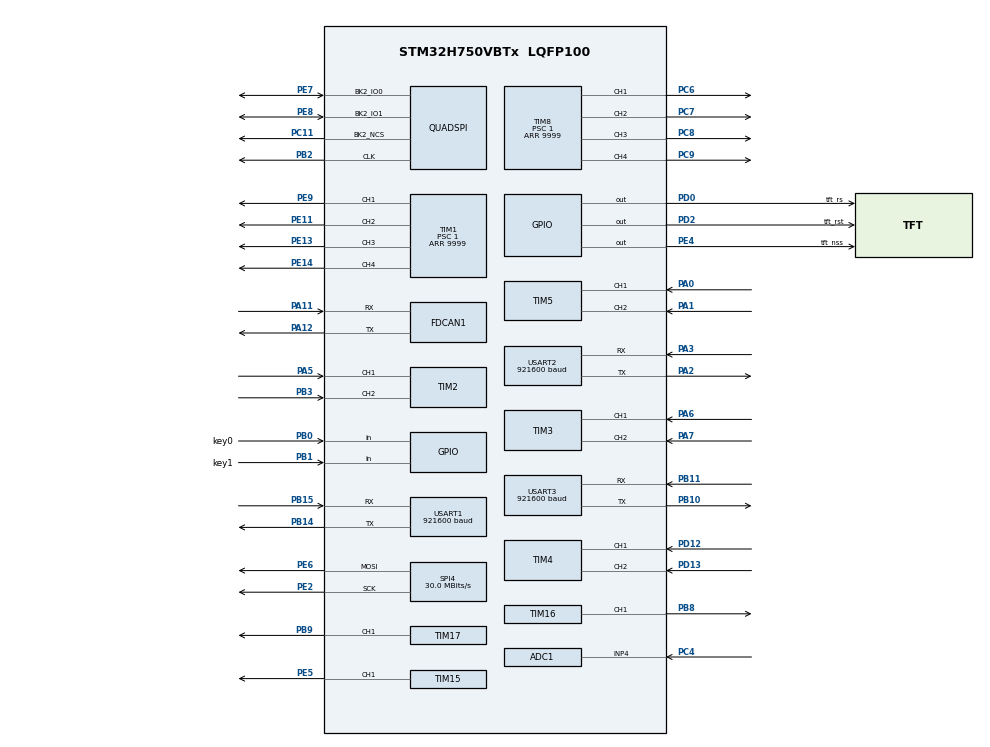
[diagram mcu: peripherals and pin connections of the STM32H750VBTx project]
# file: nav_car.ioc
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ADC1.Channel-0\#ChannelRegularConversion=ADC_CHANNEL_4
ADC1.ContinuousConvMode=ENABLE
ADC1.ConversionDataManagement=ADC_CONVERSIONDATA_DMA_CIRCULAR
ADC1.EOCSelection=ADC_EOC_SEQ_CONV
ADC1.ExternalTrigConv=ADC_SOFTWARE_START
ADC1.NbrOfConversion=1
ADC1.NbrOfConversionFlag=1
ADC1.OffsetNumber-0\#ChannelRegularConversion=ADC_OFFSET_NONE
ADC1.OffsetSignedSaturation-0\#ChannelRegularConversion=DISABLE
ADC1.Overrun=ADC_OVR_DATA_OVERWRITTEN
ADC1.Rank-0\#ChannelRegularConversion=1
ADC1.Ratio=16
ADC1.SamplingTime-0\#ChannelRegularConversion=ADC_SAMPLETIME_810CYCLES_5
ADC1.master=1
CORTEX_M7.AccessPermission_Spec=MPU_REGION_FULL_ACCESS
CORTEX_M7.BaseAddress_Spec=0x30000000
CORTEX_M7.CPU_DCache=Enabled
CORTEX_M7.CPU_ICache=Enabled
CORTEX_M7.Size_Spec=MPU_REGION_SIZE_128KB
CORTEX_M7.SubRegionDisable_Spec=0x00
CORTEX_M7.default_mode_Activation=1
Dma.ADC1.0.Direction=DMA_PERIPH_TO_MEMORY
Dma.ADC1.0.EventEnable=DISABLE
Dma.ADC1.0.FIFOMode=DMA_FIFOMODE_DISABLE
Dma.ADC1.0.Instance=DMA2_Stream0
Dma.ADC1.0.MemDataAlignment=DMA_MDATAALIGN_HALFWORD
Dma.ADC1.0.MemInc=DMA_MINC_ENABLE
Dma.ADC1.0.Mode=DMA_CIRCULAR
Dma.ADC1.0.PeriphDataAlignment=DMA_PDATAALIGN_HALFWORD
Dma.ADC1.0.PeriphInc=DMA_PINC_DISABLE
Dma.ADC1.0.Polarity=HAL_DMAMUX_REQ_GEN_RISING
Dma.ADC1.0.Priority=DMA_PRIORITY_LOW
Dma.ADC1.0.RequestNumber=1
Dma.ADC1.0.SignalID=NONE
Dma.ADC1.0.SyncEnable=DISABLE
Dma.ADC1.0.SyncPolarity=HAL_DMAMUX_SYNC_NO_EVENT
Dma.ADC1.0.SyncRequestNumber=1
Dma.ADC1.0.SyncSignalID=NONE
Dma.Request0=ADC1
Dma.Request1=TIM17_UP
Dma.TIM17_UP.1.Direction=DMA_MEMORY_TO_PERIPH
Dma.TIM17_UP.1.EventEnable=DISABLE
Dma.TIM17_UP.1.FIFOMode=DMA_FIFOMODE_DISABLE
Dma.TIM17_UP.1.Instance=DMA1_Stream0
Dma.TIM17_UP.1.MemDataAlignment=DMA_MDATAALIGN_WORD
Dma.TIM17_UP.1.MemInc=DMA_MINC_ENABLE
Dma.TIM17_UP.1.Mode=DMA_NORMAL
Dma.TIM17_UP.1.PeriphDataAlignment=DMA_PDATAALIGN_WORD
Dma.TIM17_UP.1.PeriphInc=DMA_PINC_DISABLE
Dma.TIM17_UP.1.Polarity=HAL_DMAMUX_REQ_GEN_RISING
Dma.TIM17_UP.1.Priority=DMA_PRIORITY_HIGH
Dma.TIM17_UP.1.RequestNumber=1
Dma.TIM17_UP.1.SignalID=NONE
Dma.TIM17_UP.1.SyncEnable=DISABLE
Dma.TIM17_UP.1.SyncPolarity=HAL_DMAMUX_SYNC_NO_EVENT
Dma.TIM17_UP.1.SyncRequestNumber=1
Dma.TIM17_UP.1.SyncSignalID=NONE
FDCAN1.CalculateBaudRateNominal=2604166
FDCAN1.CalculateTimeBitNominal=384
FDCAN1.CalculateTimeQuantumNominal=128.0
FREERTOS.Tasks01=lcd,8,8192,lcdTask,As weak,NULL,Dynamic,NULL,NULL;motor_control,24,1024,motorControlTask,As weak,NULL,Dynamic,NULL,NULL;uart_command,16,1024,uartCommandTask,As external,NULL,Dynamic,NULL,NULL;encoder_send,11,512,encoderSendTask,As external,NULL,Dynamic,NULL,NULL;adc,8,512,adcTask,As external,NULL,Dynamic,NULL,NULL;key,40,256,keyTask,As external,NULL,Dynamic,NULL,NULL;ws2812,9,256,ws2812Task,As external,NULL,Dynamic,NULL,NULL;beeper,10,256,beeperTask,As external,NULL,Dynamic,NULL,NULL
FREERTOS.configTOTAL_HEAP_SIZE=61440
Mcu.Family=STM32H7
Mcu.Name=STM32H750VBTx
Mcu.Package=LQFP100
NVIC.DMA2_Stream0_IRQn=true\:5\:0\:false\:false\:true\:false\:true\:true\:true
NVIC.PriorityGroup=NVIC_PRIORITYGROUP_4
NVIC.TIM6_DAC_IRQn=true\:5\:0\:false\:false\:true\:true\:true\:true\:true
NVIC.TIM7_IRQn=true\:15\:0\:false\:false\:true\:false\:false\:true\:true
NVIC.TimeBase=TIM7_IRQn
NVIC.TimeBaseIP=TIM7
NVIC.USART1_IRQn=true\:5\:0\:false\:false\:true\:true\:true\:true\:true
NVIC.USART2_IRQn=true\:5\:0\:false\:false\:true\:true\:true\:true\:true
PA0.PinAttribute=Free
PA0.Signal=S_TIM5_CH1
PA1.PinAttribute=Free
PA1.Signal=S_TIM5_CH2
PA11.Mode=FDCAN_Activate
PA11.Signal=FDCAN1_RX
PA12.Mode=FDCAN_Activate
PA12.Signal=FDCAN1_TX
PA13\ (JTMS/SWDIO).Mode=Serial_Wire
PA13\ (JTMS/SWDIO).Signal=DEBUG_JTMS-SWDIO
PA14\ (JTCK/SWCLK).Mode=Serial_Wire
PA14\ (JTCK/SWCLK).Signal=DEBUG_JTCK-SWCLK
PA2.Mode=Asynchronous
PA2.Signal=USART2_TX
PA3.Mode=Asynchronous
PA3.Signal=USART2_RX
PA5.Signal=S_TIM2_CH1_ETR
PA6.Signal=S_TIM3_CH1
PA7.Signal=S_TIM3_CH2
PB0.GPIO_Label=key0
PB0.Signal=GPIO_Input
PB1.GPIO_Label=key1
PB1.Signal=GPIO_Input
PB10.Mode=Asynchronous
PB10.Signal=USART3_TX
PB11.Mode=Asynchronous
PB11.Signal=USART3_RX
PB14.Mode=Asynchronous
PB14.Signal=USART1_TX
PB15.Mode=Asynchronous
PB15.Signal=USART1_RX
PB2.GPIO_Speed=GPIO_SPEED_FREQ_VERY_HIGH
PB2.Mode=Single Bank 2 2IOs
PB2.Signal=QUADSPI_CLK
PB3\ (JTDO/TRACESWO).Signal=S_TIM2_CH2
PB8.Signal=S_TIM16_CH1
PB9.Signal=S_TIM17_CH1
PC11.GPIO_PuPd=GPIO_PULLUP
PC11.GPIO_Speed=GPIO_SPEED_FREQ_VERY_HIGH
PC11.Mode=Single Bank 2 2IOs
PC11.Signal=QUADSPI_BK2_NCS
PC4.Signal=ADCx_INP4
PC6.Signal=S_TIM8_CH1
PC7.Signal=S_TIM8_CH2
PC8.Signal=S_TIM8_CH3
PC9.Signal=S_TIM8_CH4
PD0.GPIO_Label=tft_rs
PD0.GPIO_Speed=GPIO_SPEED_FREQ_VERY_HIGH
PD0.PinState=GPIO_PIN_SET
PD0.Signal=GPIO_Output
PD12.Signal=S_TIM4_CH1
PD13.Signal=S_TIM4_CH2
PD2.GPIO_Label=tft_rst
PD2.GPIO_Speed=GPIO_SPEED_FREQ_VERY_HIGH
PD2.PinState=GPIO_PIN_SET
PD2.Signal=GPIO_Output
PE11.Signal=S_TIM1_CH2
PE13.Signal=S_TIM1_CH3
PE14.Signal=S_TIM1_CH4
PE2.Mode=TX_Only_Simplex_Unidirect_Master
PE2.PinAttribute=Free
PE2.Signal=SPI4_SCK
PE4.GPIO_Label=tft_nss
PE4.GPIO_Speed=GPIO_SPEED_FREQ_VERY_HIGH
PE4.PinAttribute=Free
PE4.PinState=GPIO_PIN_SET
PE4.Signal=GPIO_Output
PE5.PinAttribute=Free
PE5.Signal=S_TIM15_CH1
PE6.Mode=TX_Only_Simplex_Unidirect_Master
PE6.PinAttribute=Free
PE6.Signal=SPI4_MOSI
PE7.GPIO_Speed=GPIO_SPEED_FREQ_VERY_HIGH
PE7.Mode=Single Bank 2 2IOs
PE7.Signal=QUADSPI_BK2_IO0
PE8.GPIO_Speed=GPIO_SPEED_FREQ_VERY_HIGH
PE8.Mode=Single Bank 2 2IOs
PE8.Signal=QUADSPI_BK2_IO1
PE9.Signal=S_TIM1_CH1
PH0-OSC_IN\ (PH0).Mode=HSE-External-Oscillator
PH0-OSC_IN\ (PH0).PinAttribute=Free
PH0-OSC_IN\ (PH0).Signal=RCC_OSC_IN
PH1-OSC_OUT\ (PH1).Mode=HSE-External-Oscillator
PH1-OSC_OUT\ (PH1).PinAttribute=Free
PH1-OSC_OUT\ (PH1).Signal=RCC_OSC_OUT
ProjectManager.HeapSize=0x1000
ProjectManager.StackSize=0x400
ProjectManager.TargetToolchain=CMake
QUADSPI.ClockPrescaler=1
QUADSPI.FifoThreshold=4
QUADSPI.FlashSize=24
QUADSPI.SampleShifting=QSPI_SAMPLE_SHIFTING_HALFCYCLE
RCC.ADCFreq_Value=25000000
RCC.APB1Freq_Value=120000000
RCC.APB2Freq_Value=120000000
RCC.APB3Freq_Value=120000000
RCC.APB4Freq_Value=120000000
RCC.CortexFreq_Value=480000000
RCC.D1PPRE=RCC_APB3_DIV2
RCC.D2PPRE1=RCC_APB1_DIV2
RCC.D2PPRE2=RCC_APB2_DIV2
RCC.D3PPRE=RCC_APB4_DIV2
RCC.DIVM1=5
RCC.DIVM2=2
RCC.DIVM3=5
RCC.DIVN1=192
RCC.DIVN2=40
RCC.DIVN3=70
RCC.DIVP2=20
RCC.DIVQ1=5
RCC.DIVQ2=4
RCC.DIVQ3=5
RCC.DIVR2=5
RCC.DIVR3=5
RCC.EnbaleCSS=true
RCC.FDCANCLockSelection=RCC_FDCANCLKSOURCE_PLL2
RCC.HCLKFreq_Value=240000000
RCC.HPRE=RCC_HCLK_DIV2
RCC.PLL2FRACN=0
RCC.PLL3FRACN=0
RCC.PLLFRACN=0
RCC.PLLSourceVirtual=RCC_PLLSOURCE_HSE
RCC.QSPICLockSelection=RCC_QSPICLKSOURCE_PLL2
RCC.SYSCLKFreq_VALUE=480000000
RCC.SYSCLKSource=RCC_SYSCLKSOURCE_PLLCLK
RCC.USART234578CLockSelection=RCC_USART234578CLKSOURCE_PLL3
RCC.USBFreq_Value=192000000
SH.ADCx_INP4.0=ADC1_INP4,IN4-Single-Ended
SH.S_TIM15_CH1.0=TIM15_CH1,PWM Generation1 CH1
SH.S_TIM16_CH1.0=TIM16_CH1,PWM Generation1 CH1
SH.S_TIM17_CH1.0=TIM17_CH1,PWM Generation1 CH1
SH.S_TIM1_CH1.0=TIM1_CH1,PWM Generation1 CH1
SH.S_TIM1_CH2.0=TIM1_CH2,PWM Generation2 CH2
SH.S_TIM1_CH3.0=TIM1_CH3,PWM Generation3 CH3
SH.S_TIM1_CH4.0=TIM1_CH4,PWM Generation4 CH4
SH.S_TIM2_CH1_ETR.0=TIM2_CH1,Encoder_Interface
SH.S_TIM2_CH2.0=TIM2_CH2,Encoder_Interface
SH.S_TIM3_CH1.0=TIM3_CH1,Encoder_Interface
SH.S_TIM3_CH2.0=TIM3_CH2,Encoder_Interface
SH.S_TIM4_CH1.0=TIM4_CH1,Encoder_Interface
SH.S_TIM4_CH2.0=TIM4_CH2,Encoder_Interface
SH.S_TIM5_CH1.0=TIM5_CH1,Encoder_Interface
SH.S_TIM5_CH2.0=TIM5_CH2,Encoder_Interface
SH.S_TIM8_CH1.0=TIM8_CH1,PWM Generation1 CH1
SH.S_TIM8_CH2.0=TIM8_CH2,PWM Generation2 CH2
SH.S_TIM8_CH3.0=TIM8_CH3,PWM Generation3 CH3
SH.S_TIM8_CH4.0=TIM8_CH4,PWM Generation4 CH4
SPI4.BaudRatePrescaler=SPI_BAUDRATEPRESCALER_4
SPI4.CalculateBaudRate=30.0 MBits/s
SPI4.DataSize=SPI_DATASIZE_8BIT
SPI4.Direction=SPI_DIRECTION_2LINES_TXONLY
SPI4.Mode=SPI_MODE_MASTER
SPI4.VirtualType=VM_MASTER
TIM1.AutoReloadPreload=TIM_AUTORELOAD_PRELOAD_ENABLE
TIM1.Channel-PWM\ Generation1\ CH1=TIM_CHANNEL_1
TIM1.Channel-PWM\ Generation2\ CH2=TIM_CHANNEL_2
TIM1.Channel-PWM\ Generation3\ CH3=TIM_CHANNEL_3
TIM1.Channel-PWM\ Generation4\ CH4=TIM_CHANNEL_4
TIM1.Period=9999
TIM1.Prescaler=1
TIM12.AutoReloadPreload=TIM_AUTORELOAD_PRELOAD_ENABLE
TIM12.Period=65535
TIM12.Prescaler=239
TIM12.TIM_MasterOutputTrigger=TIM_TRGO_UPDATE
TIM12.TIM_MasterSlaveMode=TIM_MASTERSLAVEMODE_ENABLE
TIM15.Channel-PWM\ Generation1\ CH1=TIM_CHANNEL_1
TIM15.Period=49
TIM15.Prescaler=119
TIM16.Channel=TIM_CHANNEL_1
TIM16.Prescaler=239
TIM17.Channel=TIM_CHANNEL_1
TIM17.Period=299
TIM6.AutoReloadPreload=TIM_AUTORELOAD_PRELOAD_ENABLE
TIM6.Period=999
TIM6.Prescaler=239
TIM6.TIM_MasterOutputTrigger=TIM_TRGO_UPDATE
TIM8.AutoReloadPreload=TIM_AUTORELOAD_PRELOAD_ENABLE
TIM8.Channel-PWM\ Generation1\ CH1=TIM_CHANNEL_1
TIM8.Channel-PWM\ Generation2\ CH2=TIM_CHANNEL_2
TIM8.Channel-PWM\ Generation3\ CH3=TIM_CHANNEL_3
TIM8.Channel-PWM\ Generation4\ CH4=TIM_CHANNEL_4
TIM8.Period=9999
TIM8.Prescaler=1
USART1.BaudRate=921600
USART1.VirtualMode-Asynchronous=VM_ASYNC
USART2.BaudRate=921600
USART2.VirtualMode-Asynchronous=VM_ASYNC
USART3.BaudRate=921600
USART3.VirtualMode-Asynchronous=VM_ASYNC
VP_CRC_VS_CRC.Mode=CRC_Activate
VP_FREERTOS_VS_CMSIS_V2.Mode=CMSIS_V2
VP_MEMORYMAP_VS_MEMORYMAP.Mode=CurAppReg
VP_SYS_VS_tim7.Mode=TIM7
VP_TIM12_VS_ClockSourceINT.Mode=Internal
VP_TIM15_VS_ClockSourceINT.Mode=Internal
VP_TIM16_VS_ClockSourceINT.Mode=Enable_Timer
VP_TIM17_VS_ClockSourceINT.Mode=Enable_Timer
VP_TIM6_VS_ClockSourceINT.Mode=Enable_Timer
board=custom

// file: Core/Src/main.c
/* USER CODE BEGIN Header */
/**
  ******************************************************************************
  * @file           : main.c
  * @brief          : Main program body
  ******************************************************************************
  * @attention
  *
  * Copyright (c) 2026 STMicroelectronics.
  * All rights reserved.
  *
  * This software is licensed under terms that can be found in the LICENSE file
  * in the root directory of this software component.
  * If no LICENSE file comes with this software, it is provided AS-IS.
  *
  ******************************************************************************
  */
/* USER CODE END Header */
#include "main.h"
#include "FreeRTOS.h"
#include "cmsis_os2.h"

/* USER CODE BEGIN Includes */
#include <stdio.h>
/* USER CODE END Includes */

ADC_HandleTypeDef hadc1;
DMA_HandleTypeDef hdma_adc1;

CRC_HandleTypeDef hcrc;

FDCAN_HandleTypeDef hfdcan1;

QSPI_HandleTypeDef hqspi;

SPI_HandleTypeDef hspi4;

TIM_HandleTypeDef htim1;
TIM_HandleTypeDef htim2;
TIM_HandleTypeDef htim3;
TIM_HandleTypeDef htim4;
TIM_HandleTypeDef htim5;
TIM_HandleTypeDef htim6;
TIM_HandleTypeDef htim8;
TIM_HandleTypeDef htim12;
TIM_HandleTypeDef htim15;
TIM_HandleTypeDef htim16;
TIM_HandleTypeDef htim17;
DMA_HandleTypeDef hdma_tim17_up;

UART_HandleTypeDef huart1;
UART_HandleTypeDef huart2;
UART_HandleTypeDef huart3;

/* Definitions for lcd */
osThreadId_t lcdHandle;
const osThreadAttr_t lcd_attributes = {
  .name = "lcd",
  .stack_size = 8192 * 4,
  .priority = (osPriority_t) osPriorityLow,
};
/* Definitions for motor_control */
osThreadId_t motor_controlHandle;
const osThreadAttr_t motor_control_attributes = {
  .name = "motor_control",
  .stack_size = 1024 * 4,
  .priority = (osPriority_t) osPriorityNormal,
};
/* Definitions for uart_command */
osThreadId_t uart_commandHandle;
const osThreadAttr_t uart_command_attributes = {
  .name = "uart_command",
  .stack_size = 1024 * 4,
  .priority = (osPriority_t) osPriorityBelowNormal,
};
/* Definitions for encoder_send */
osThreadId_t encoder_sendHandle;
const osThreadAttr_t encoder_send_attributes = {
  .name = "encoder_send",
  .stack_size = 512 * 4,
  .priority = (osPriority_t) osPriorityLow3,
};
/* Definitions for adc */
osThreadId_t adcHandle;
const osThreadAttr_t adc_attributes = {
  .name = "adc",
  .stack_size = 512 * 4,
  .priority = (osPriority_t) osPriorityLow,
};
/* Definitions for key */
osThreadId_t keyHandle;
const osThreadAttr_t key_attributes = {
  .name = "key",
  .stack_size = 256 * 4,
  .priority = (osPriority_t) osPriorityHigh,
};
/* Definitions for ws2812 */
osThreadId_t ws2812Handle;
const osThreadAttr_t ws2812_attributes = {
  .name = "ws2812",
  .stack_size = 256 * 4,
  .priority = (osPriority_t) osPriorityLow1,
};
/* Definitions for beeper */
osThreadId_t beeperHandle;
const osThreadAttr_t beeper_attributes = {
  .name = "beeper",
  .stack_size = 256 * 4,
  .priority = (osPriority_t) osPriorityLow2,
};

void SystemClock_Config(void);
void PeriphCommonClock_Config(void);
static void MPU_Config(void);
static void MX_GPIO_Init(void);
static void MX_DMA_Init(void);
static void MX_TIM1_Init(void);
static void MX_TIM2_Init(void);
static void MX_TIM3_Init(void);
static void MX_TIM4_Init(void);
static void MX_TIM5_Init(void);
static void MX_TIM6_Init(void);
static void MX_USART1_UART_Init(void);
static void MX_USART2_UART_Init(void);
static void MX_USART3_UART_Init(void);
static void MX_CRC_Init(void);
static void MX_FDCAN1_Init(void);
static void MX_TIM8_Init(void);
static void MX_ADC1_Init(void);
static void MX_QUADSPI_Init(void);
static void MX_SPI4_Init(void);
static void MX_TIM15_Init(void);
static void MX_TIM16_Init(void);
static void MX_TIM12_Init(void);
static void MX_TIM17_Init(void);
void lcdTask(void *argument);
void motorControlTask(void *argument);
extern void uartCommandTask(void *argument);
extern void encoderSendTask(void *argument);
extern void adcTask(void *argument);
extern void keyTask(void *argument);
extern void ws2812Task(void *argument);
extern void beeperTask(void *argument);

/* USER CODE BEGIN 0 */
volatile uint64_t timestamp_us = 0; // 全局 64-bit 时间戳（微秒）
volatile uint32_t runtime_base32 = 0; // FreeRTOS 统计用 32-bit 时间戳（微秒）
/* USER CODE END 0 */

int main(void)
{

  /* MPU Configuration--------------------------------------------------------*/
  MPU_Config();

  /* Enable the CPU Cache */

  /* Enable I-Cache---------------------------------------------------------*/
  SCB_EnableICache();

  /* Enable D-Cache---------------------------------------------------------*/
  SCB_EnableDCache();

  /* MCU Configuration--------------------------------------------------------*/

  /* Reset of all peripherals, Initializes the Flash interface and the Systick. */
  HAL_Init();

  /* Configure the system clock */
  SystemClock_Config();

  /* Configure the peripherals common clocks */
  PeriphCommonClock_Config();

  /* Initialize all configured peripherals */
  MX_GPIO_Init();
  MX_DMA_Init();
  MX_TIM1_Init();
  MX_TIM2_Init();
  MX_TIM3_Init();
  MX_TIM4_Init();
  MX_TIM5_Init();
  MX_TIM6_Init();
  MX_USART1_UART_Init();
  MX_USART2_UART_Init();
  MX_USART3_UART_Init();
  MX_CRC_Init();
  MX_FDCAN1_Init();
  MX_TIM8_Init();
  MX_ADC1_Init();
  MX_QUADSPI_Init();
  MX_SPI4_Init();
  MX_TIM15_Init();
  MX_TIM16_Init();
  MX_TIM12_Init();
  MX_TIM17_Init();
  /* USER CODE BEGIN 2 */
    __HAL_TIM_SET_COUNTER(&htim12, 0);
    __HAL_TIM_CLEAR_FLAG(&htim12, TIM_FLAG_UPDATE);
    HAL_TIM_Base_Start_IT(&htim12);
  /* USER CODE END 2 */

  /* Init scheduler */
  osKernelInitialize();

  /* Create the thread(s) */
  /* creation of lcd */
  lcdHandle = osThreadNew(lcdTask, NULL, &lcd_attributes);

  /* creation of motor_control */
  motor_controlHandle = osThreadNew(motorControlTask, NULL, &motor_control_attributes);

  /* creation of uart_command */
  uart_commandHandle = osThreadNew(uartCommandTask, NULL, &uart_command_attributes);

  /* creation of encoder_send */
  encoder_sendHandle = osThreadNew(encoderSendTask, NULL, &encoder_send_attributes);

  /* creation of adc */
  adcHandle = osThreadNew(adcTask, NULL, &adc_attributes);

  /* creation of key */
  keyHandle = osThreadNew(keyTask, NULL, &key_attributes);

  /* creation of ws2812 */
  ws2812Handle = osThreadNew(ws2812Task, NULL, &ws2812_attributes);

  /* creation of beeper */
  beeperHandle = osThreadNew(beeperTask, NULL, &beeper_attributes);

  /* Start scheduler */
  osKernelStart();

  /* We should never get here as control is now taken by the scheduler */

  /* Infinite loop */
  while (1)
  {

  }
}

void SystemClock_Config(void)
{
  RCC_OscInitTypeDef RCC_OscInitStruct = {0};
  RCC_ClkInitTypeDef RCC_ClkInitStruct = {0};

  /** Supply configuration update enable
  */
  HAL_PWREx_ConfigSupply(PWR_LDO_SUPPLY);

  /** Configure the main internal regulator output voltage
  */
  __HAL_PWR_VOLTAGESCALING_CONFIG(PWR_REGULATOR_VOLTAGE_SCALE0);

  while(!__HAL_PWR_GET_FLAG(PWR_FLAG_VOSRDY)) {}

  /** Initializes the RCC Oscillators according to the specified parameters
  * in the RCC_OscInitTypeDef structure.
  */
  RCC_OscInitStruct.OscillatorType = RCC_OSCILLATORTYPE_HSE;
  RCC_OscInitStruct.HSEState = RCC_HSE_ON;
  RCC_OscInitStruct.PLL.PLLState = RCC_PLL_ON;
  RCC_OscInitStruct.PLL.PLLSource = RCC_PLLSOURCE_HSE;
  RCC_OscInitStruct.PLL.PLLM = 5;
  RCC_OscInitStruct.PLL.PLLN = 192;
  RCC_OscInitStruct.PLL.PLLP = 2;
  RCC_OscInitStruct.PLL.PLLQ = 5;
  RCC_OscInitStruct.PLL.PLLR = 2;
  RCC_OscInitStruct.PLL.PLLRGE = RCC_PLL1VCIRANGE_2;
  RCC_OscInitStruct.PLL.PLLVCOSEL = RCC_PLL1VCOWIDE;
  RCC_OscInitStruct.PLL.PLLFRACN = 0;
  if (HAL_RCC_OscConfig(&RCC_OscInitStruct) != HAL_OK)
  {
    Error_Handler();
  }

  /** Initializes the CPU, AHB and APB buses clocks
  */
  RCC_ClkInitStruct.ClockType = RCC_CLOCKTYPE_HCLK|RCC_CLOCKTYPE_SYSCLK
                              |RCC_CLOCKTYPE_PCLK1|RCC_CLOCKTYPE_PCLK2
                              |RCC_CLOCKTYPE_D3PCLK1|RCC_CLOCKTYPE_D1PCLK1;
  RCC_ClkInitStruct.SYSCLKSource = RCC_SYSCLKSOURCE_PLLCLK;
  RCC_ClkInitStruct.SYSCLKDivider = RCC_SYSCLK_DIV1;
  RCC_ClkInitStruct.AHBCLKDivider = RCC_HCLK_DIV2;
  RCC_ClkInitStruct.APB3CLKDivider = RCC_APB3_DIV2;
  RCC_ClkInitStruct.APB1CLKDivider = RCC_APB1_DIV2;
  RCC_ClkInitStruct.APB2CLKDivider = RCC_APB2_DIV2;
  RCC_ClkInitStruct.APB4CLKDivider = RCC_APB4_DIV2;

  if (HAL_RCC_ClockConfig(&RCC_ClkInitStruct, FLASH_LATENCY_4) != HAL_OK)
  {
    Error_Handler();
  }

  /** Enables the Clock Security System
  */
  HAL_RCC_EnableCSS();
}

void PeriphCommonClock_Config(void)
{
  RCC_PeriphCLKInitTypeDef PeriphClkInitStruct = {0};

  /** Initializes the peripherals clock
  */
  PeriphClkInitStruct.PeriphClockSelection = RCC_PERIPHCLK_QSPI|RCC_PERIPHCLK_ADC
                              |RCC_PERIPHCLK_FDCAN|RCC_PERIPHCLK_USART2
                              |RCC_PERIPHCLK_USART3;
  PeriphClkInitStruct.PLL2.PLL2M = 2;
  PeriphClkInitStruct.PLL2.PLL2N = 40;
  PeriphClkInitStruct.PLL2.PLL2P = 20;
  PeriphClkInitStruct.PLL2.PLL2Q = 4;
  PeriphClkInitStruct.PLL2.PLL2R = 5;
  PeriphClkInitStruct.PLL2.PLL2RGE = RCC_PLL2VCIRANGE_3;
  PeriphClkInitStruct.PLL2.PLL2VCOSEL = RCC_PLL2VCOWIDE;
  PeriphClkInitStruct.PLL2.PLL2FRACN = 0;
  PeriphClkInitStruct.PLL3.PLL3M = 5;
  PeriphClkInitStruct.PLL3.PLL3N = 70;
  PeriphClkInitStruct.PLL3.PLL3P = 2;
  PeriphClkInitStruct.PLL3.PLL3Q = 5;
  PeriphClkInitStruct.PLL3.PLL3R = 5;
  PeriphClkInitStruct.PLL3.PLL3RGE = RCC_PLL3VCIRANGE_2;
  PeriphClkInitStruct.PLL3.PLL3VCOSEL = RCC_PLL3VCOWIDE;
  PeriphClkInitStruct.PLL3.PLL3FRACN = 0;
  PeriphClkInitStruct.QspiClockSelection = RCC_QSPICLKSOURCE_PLL2;
  PeriphClkInitStruct.FdcanClockSelection = RCC_FDCANCLKSOURCE_PLL2;
  PeriphClkInitStruct.Usart234578ClockSelection = RCC_USART234578CLKSOURCE_PLL3;
  PeriphClkInitStruct.AdcClockSelection = RCC_ADCCLKSOURCE_PLL2;
  if (HAL_RCCEx_PeriphCLKConfig(&PeriphClkInitStruct) != HAL_OK)
  {
    Error_Handler();
  }
}

static void MX_ADC1_Init(void)
{

  ADC_MultiModeTypeDef multimode = {0};
  ADC_ChannelConfTypeDef sConfig = {0};

  /** Common config
  */
  hadc1.Instance = ADC1;
  hadc1.Init.ClockPrescaler = ADC_CLOCK_ASYNC_DIV1;
  hadc1.Init.Resolution = ADC_RESOLUTION_16B;
  hadc1.Init.ScanConvMode = ADC_SCAN_DISABLE;
  hadc1.Init.EOCSelection = ADC_EOC_SEQ_CONV;
  hadc1.Init.LowPowerAutoWait = DISABLE;
  hadc1.Init.ContinuousConvMode = ENABLE;
  hadc1.Init.NbrOfConversion = 1;
  hadc1.Init.DiscontinuousConvMode = DISABLE;
  hadc1.Init.ExternalTrigConv = ADC_SOFTWARE_START;
  hadc1.Init.ExternalTrigConvEdge = ADC_EXTERNALTRIGCONVEDGE_NONE;
  hadc1.Init.ConversionDataManagement = ADC_CONVERSIONDATA_DMA_CIRCULAR;
  hadc1.Init.Overrun = ADC_OVR_DATA_OVERWRITTEN;
  hadc1.Init.LeftBitShift = ADC_LEFTBITSHIFT_NONE;
  hadc1.Init.OversamplingMode = DISABLE;
  hadc1.Init.Oversampling.Ratio = 16;
  if (HAL_ADC_Init(&hadc1) != HAL_OK)
  {
    Error_Handler();
  }

  /** Configure the ADC multi-mode
  */
  multimode.Mode = ADC_MODE_INDEPENDENT;
  if (HAL_ADCEx_MultiModeConfigChannel(&hadc1, &multimode) != HAL_OK)
  {
    Error_Handler();
  }

  /** Configure Regular Channel
  */
  sConfig.Channel = ADC_CHANNEL_4;
  sConfig.Rank = ADC_REGULAR_RANK_1;
  sConfig.SamplingTime = ADC_SAMPLETIME_810CYCLES_5;
  sConfig.SingleDiff = ADC_SINGLE_ENDED;
  sConfig.OffsetNumber = ADC_OFFSET_NONE;
  sConfig.Offset = 0;
  sConfig.OffsetSignedSaturation = DISABLE;
  if (HAL_ADC_ConfigChannel(&hadc1, &sConfig) != HAL_OK)
  {
    Error_Handler();
  }

}

static void MX_CRC_Init(void)
{

  hcrc.Instance = CRC;
  hcrc.Init.DefaultPolynomialUse = DEFAULT_POLYNOMIAL_ENABLE;
  hcrc.Init.DefaultInitValueUse = DEFAULT_INIT_VALUE_ENABLE;
  hcrc.Init.InputDataInversionMode = CRC_INPUTDATA_INVERSION_NONE;
  hcrc.Init.OutputDataInversionMode = CRC_OUTPUTDATA_INVERSION_DISABLE;
  hcrc.InputDataFormat = CRC_INPUTDATA_FORMAT_BYTES;
  if (HAL_CRC_Init(&hcrc) != HAL_OK)
  {
    Error_Handler();
  }

}

static void MX_FDCAN1_Init(void)
{

  hfdcan1.Instance = FDCAN1;
  hfdcan1.Init.FrameFormat = FDCAN_FRAME_CLASSIC;
  hfdcan1.Init.Mode = FDCAN_MODE_NORMAL;
  hfdcan1.Init.AutoRetransmission = DISABLE;
  hfdcan1.Init.TransmitPause = DISABLE;
  hfdcan1.Init.ProtocolException = DISABLE;
  hfdcan1.Init.NominalPrescaler = 16;
  hfdcan1.Init.NominalSyncJumpWidth = 1;
  hfdcan1.Init.NominalTimeSeg1 = 1;
  hfdcan1.Init.NominalTimeSeg2 = 1;
  hfdcan1.Init.DataPrescaler = 1;
  hfdcan1.Init.DataSyncJumpWidth = 1;
  hfdcan1.Init.DataTimeSeg1 = 1;
  hfdcan1.Init.DataTimeSeg2 = 1;
  hfdcan1.Init.MessageRAMOffset = 0;
  hfdcan1.Init.StdFiltersNbr = 0;
  hfdcan1.Init.ExtFiltersNbr = 0;
  hfdcan1.Init.RxFifo0ElmtsNbr = 0;
  hfdcan1.Init.RxFifo0ElmtSize = FDCAN_DATA_BYTES_8;
  hfdcan1.Init.RxFifo1ElmtsNbr = 0;
  hfdcan1.Init.RxFifo1ElmtSize = FDCAN_DATA_BYTES_8;
  hfdcan1.Init.RxBuffersNbr = 0;
  hfdcan1.Init.RxBufferSize = FDCAN_DATA_BYTES_8;
  hfdcan1.Init.TxEventsNbr = 0;
  hfdcan1.Init.TxBuffersNbr = 0;
  hfdcan1.Init.TxFifoQueueElmtsNbr = 0;
  hfdcan1.Init.TxFifoQueueMode = FDCAN_TX_FIFO_OPERATION;
  hfdcan1.Init.TxElmtSize = FDCAN_DATA_BYTES_8;
  if (HAL_FDCAN_Init(&hfdcan1) != HAL_OK)
  {
    Error_Handler();
  }

}

static void MX_QUADSPI_Init(void)
{

  /* QUADSPI parameter configuration*/
  hqspi.Instance = QUADSPI;
  hqspi.Init.ClockPrescaler = 1;
  hqspi.Init.FifoThreshold = 4;
  hqspi.Init.SampleShifting = QSPI_SAMPLE_SHIFTING_HALFCYCLE;
  hqspi.Init.FlashSize = 24;
  hqspi.Init.ChipSelectHighTime = QSPI_CS_HIGH_TIME_1_CYCLE;
  hqspi.Init.ClockMode = QSPI_CLOCK_MODE_0;
  hqspi.Init.FlashID = QSPI_FLASH_ID_2;
  hqspi.Init.DualFlash = QSPI_DUALFLASH_DISABLE;
  if (HAL_QSPI_Init(&hqspi) != HAL_OK)
  {
    Error_Handler();
  }

}

static void MX_SPI4_Init(void)
{

  /* SPI4 parameter configuration*/
  hspi4.Instance = SPI4;
  hspi4.Init.Mode = SPI_MODE_MASTER;
  hspi4.Init.Direction = SPI_DIRECTION_2LINES_TXONLY;
  hspi4.Init.DataSize = SPI_DATASIZE_8BIT;
  hspi4.Init.CLKPolarity = SPI_POLARITY_LOW;
  hspi4.Init.CLKPhase = SPI_PHASE_1EDGE;
  hspi4.Init.NSS = SPI_NSS_SOFT;
  hspi4.Init.BaudRatePrescaler = SPI_BAUDRATEPRESCALER_4;
  hspi4.Init.FirstBit = SPI_FIRSTBIT_MSB;
  hspi4.Init.TIMode = SPI_TIMODE_DISABLE;
  hspi4.Init.CRCCalculation = SPI_CRCCALCULATION_DISABLE;
  hspi4.Init.CRCPolynomial = 0x0;
  hspi4.Init.NSSPMode = SPI_NSS_PULSE_ENABLE;
  hspi4.Init.NSSPolarity = SPI_NSS_POLARITY_LOW;
  hspi4.Init.FifoThreshold = SPI_FIFO_THRESHOLD_01DATA;
  hspi4.Init.TxCRCInitializationPattern = SPI_CRC_INITIALIZATION_ALL_ZERO_PATTERN;
  hspi4.Init.RxCRCInitializationPattern = SPI_CRC_INITIALIZATION_ALL_ZERO_PATTERN;
  hspi4.Init.MasterSSIdleness = SPI_MASTER_SS_IDLENESS_00CYCLE;
  hspi4.Init.MasterInterDataIdleness = SPI_MASTER_INTERDATA_IDLENESS_00CYCLE;
  hspi4.Init.MasterReceiverAutoSusp = SPI_MASTER_RX_AUTOSUSP_DISABLE;
  hspi4.Init.MasterKeepIOState = SPI_MASTER_KEEP_IO_STATE_DISABLE;
  hspi4.Init.IOSwap = SPI_IO_SWAP_DISABLE;
  if (HAL_SPI_Init(&hspi4) != HAL_OK)
  {
    Error_Handler();
  }

}

static void MX_TIM1_Init(void)
{

  TIM_MasterConfigTypeDef sMasterConfig = {0};
  TIM_OC_InitTypeDef sConfigOC = {0};
  TIM_BreakDeadTimeConfigTypeDef sBreakDeadTimeConfig = {0};

  htim1.Instance = TIM1;
  htim1.Init.Prescaler = 1;
  htim1.Init.CounterMode = TIM_COUNTERMODE_UP;
  htim1.Init.Period = 9999;
  htim1.Init.ClockDivision = TIM_CLOCKDIVISION_DIV1;
  htim1.Init.RepetitionCounter = 0;
  htim1.Init.AutoReloadPreload = TIM_AUTORELOAD_PRELOAD_ENABLE;
  if (HAL_TIM_PWM_Init(&htim1) != HAL_OK)
  {
    Error_Handler();
  }
  sMasterConfig.MasterOutputTrigger = TIM_TRGO_RESET;
  sMasterConfig.MasterOutputTrigger2 = TIM_TRGO2_RESET;
  sMasterConfig.MasterSlaveMode = TIM_MASTERSLAVEMODE_DISABLE;
  if (HAL_TIMEx_MasterConfigSynchronization(&htim1, &sMasterConfig) != HAL_OK)
  {
    Error_Handler();
  }
  sConfigOC.OCMode = TIM_OCMODE_PWM1;
  sConfigOC.Pulse = 0;
  sConfigOC.OCPolarity = TIM_OCPOLARITY_HIGH;
  sConfigOC.OCNPolarity = TIM_OCNPOLARITY_HIGH;
  sConfigOC.OCFastMode = TIM_OCFAST_DISABLE;
  sConfigOC.OCIdleState = TIM_OCIDLESTATE_RESET;
  sConfigOC.OCNIdleState = TIM_OCNIDLESTATE_RESET;
  if (HAL_TIM_PWM_ConfigChannel(&htim1, &sConfigOC, TIM_CHANNEL_1) != HAL_OK)
  {
    Error_Handler();
  }
  if (HAL_TIM_PWM_ConfigChannel(&htim1, &sConfigOC, TIM_CHANNEL_2) != HAL_OK)
  {
    Error_Handler();
  }
  if (HAL_TIM_PWM_ConfigChannel(&htim1, &sConfigOC, TIM_CHANNEL_3) != HAL_OK)
  {
    Error_Handler();
  }
  if (HAL_TIM_PWM_ConfigChannel(&htim1, &sConfigOC, TIM_CHANNEL_4) != HAL_OK)
  {
    Error_Handler();
  }
  sBreakDeadTimeConfig.OffStateRunMode = TIM_OSSR_DISABLE;
  sBreakDeadTimeConfig.OffStateIDLEMode = TIM_OSSI_DISABLE;
  sBreakDeadTimeConfig.LockLevel = TIM_LOCKLEVEL_OFF;
  sBreakDeadTimeConfig.DeadTime = 0;
  sBreakDeadTimeConfig.BreakState = TIM_BREAK_DISABLE;
  sBreakDeadTimeConfig.BreakPolarity = TIM_BREAKPOLARITY_HIGH;
  sBreakDeadTimeConfig.BreakFilter = 0;
  sBreakDeadTimeConfig.Break2State = TIM_BREAK2_DISABLE;
  sBreakDeadTimeConfig.Break2Polarity = TIM_BREAK2POLARITY_HIGH;
  sBreakDeadTimeConfig.Break2Filter = 0;
  sBreakDeadTimeConfig.AutomaticOutput = TIM_AUTOMATICOUTPUT_DISABLE;
  if (HAL_TIMEx_ConfigBreakDeadTime(&htim1, &sBreakDeadTimeConfig) != HAL_OK)
  {
    Error_Handler();
  }
  HAL_TIM_MspPostInit(&htim1);

}

static void MX_TIM2_Init(void)
{

  TIM_Encoder_InitTypeDef sConfig = {0};
  TIM_MasterConfigTypeDef sMasterConfig = {0};

  htim2.Instance = TIM2;
  htim2.Init.Prescaler = 0;
  htim2.Init.CounterMode = TIM_COUNTERMODE_UP;
  htim2.Init.Period = 4294967295;
  htim2.Init.ClockDivision = TIM_CLOCKDIVISION_DIV1;
  htim2.Init.AutoReloadPreload = TIM_AUTORELOAD_PRELOAD_DISABLE;
  sConfig.EncoderMode = TIM_ENCODERMODE_TI1;
  sConfig.IC1Polarity = TIM_ICPOLARITY_RISING;
  sConfig.IC1Selection = TIM_ICSELECTION_DIRECTTI;
  sConfig.IC1Prescaler = TIM_ICPSC_DIV1;
  sConfig.IC1Filter = 0;
  sConfig.IC2Polarity = TIM_ICPOLARITY_RISING;
  sConfig.IC2Selection = TIM_ICSELECTION_DIRECTTI;
  sConfig.IC2Prescaler = TIM_ICPSC_DIV1;
  sConfig.IC2Filter = 0;
  if (HAL_TIM_Encoder_Init(&htim2, &sConfig) != HAL_OK)
  {
    Error_Handler();
  }
  sMasterConfig.MasterOutputTrigger = TIM_TRGO_RESET;
  sMasterConfig.MasterSlaveMode = TIM_MASTERSLAVEMODE_DISABLE;
  if (HAL_TIMEx_MasterConfigSynchronization(&htim2, &sMasterConfig) != HAL_OK)
  {
    Error_Handler();
  }

}

static void MX_TIM3_Init(void)
{

  TIM_Encoder_InitTypeDef sConfig = {0};
  TIM_MasterConfigTypeDef sMasterConfig = {0};

  htim3.Instance = TIM3;
  htim3.Init.Prescaler = 0;
  htim3.Init.CounterMode = TIM_COUNTERMODE_UP;
  htim3.Init.Period = 65535;
  htim3.Init.ClockDivision = TIM_CLOCKDIVISION_DIV1;
  htim3.Init.AutoReloadPreload = TIM_AUTORELOAD_PRELOAD_DISABLE;
  sConfig.EncoderMode = TIM_ENCODERMODE_TI1;
  sConfig.IC1Polarity = TIM_ICPOLARITY_RISING;
  sConfig.IC1Selection = TIM_ICSELECTION_DIRECTTI;
  sConfig.IC1Prescaler = TIM_ICPSC_DIV1;
  sConfig.IC1Filter = 0;
  sConfig.IC2Polarity = TIM_ICPOLARITY_RISING;
  sConfig.IC2Selection = TIM_ICSELECTION_DIRECTTI;
  sConfig.IC2Prescaler = TIM_ICPSC_DIV1;
  sConfig.IC2Filter = 0;
  if (HAL_TIM_Encoder_Init(&htim3, &sConfig) != HAL_OK)
  {
    Error_Handler();
  }
  sMasterConfig.MasterOutputTrigger = TIM_TRGO_RESET;
  sMasterConfig.MasterSlaveMode = TIM_MASTERSLAVEMODE_DISABLE;
  if (HAL_TIMEx_MasterConfigSynchronization(&htim3, &sMasterConfig) != HAL_OK)
  {
    Error_Handler();
  }

}

static void MX_TIM4_Init(void)
{

  TIM_Encoder_InitTypeDef sConfig = {0};
  TIM_MasterConfigTypeDef sMasterConfig = {0};

  htim4.Instance = TIM4;
  htim4.Init.Prescaler = 0;
  htim4.Init.CounterMode = TIM_COUNTERMODE_UP;
  htim4.Init.Period = 65535;
  htim4.Init.ClockDivision = TIM_CLOCKDIVISION_DIV1;
  htim4.Init.AutoReloadPreload = TIM_AUTORELOAD_PRELOAD_DISABLE;
  sConfig.EncoderMode = TIM_ENCODERMODE_TI1;
  sConfig.IC1Polarity = TIM_ICPOLARITY_RISING;
  sConfig.IC1Selection = TIM_ICSELECTION_DIRECTTI;
  sConfig.IC1Prescaler = TIM_ICPSC_DIV1;
  sConfig.IC1Filter = 0;
  sConfig.IC2Polarity = TIM_ICPOLARITY_RISING;
  sConfig.IC2Selection = TIM_ICSELECTION_DIRECTTI;
  sConfig.IC2Prescaler = TIM_ICPSC_DIV1;
  sConfig.IC2Filter = 0;
  if (HAL_TIM_Encoder_Init(&htim4, &sConfig) != HAL_OK)
  {
    Error_Handler();
  }
  sMasterConfig.MasterOutputTrigger = TIM_TRGO_RESET;
  sMasterConfig.MasterSlaveMode = TIM_MASTERSLAVEMODE_DISABLE;
  if (HAL_TIMEx_MasterConfigSynchronization(&htim4, &sMasterConfig) != HAL_OK)
  {
    Error_Handler();
  }

}

static void MX_TIM5_Init(void)
{

  TIM_Encoder_InitTypeDef sConfig = {0};
  TIM_MasterConfigTypeDef sMasterConfig = {0};

  htim5.Instance = TIM5;
  htim5.Init.Prescaler = 0;
  htim5.Init.CounterMode = TIM_COUNTERMODE_UP;
  htim5.Init.Period = 4294967295;
  htim5.Init.ClockDivision = TIM_CLOCKDIVISION_DIV1;
  htim5.Init.AutoReloadPreload = TIM_AUTORELOAD_PRELOAD_DISABLE;
  sConfig.EncoderMode = TIM_ENCODERMODE_TI1;
  sConfig.IC1Polarity = TIM_ICPOLARITY_RISING;
  sConfig.IC1Selection = TIM_ICSELECTION_DIRECTTI;
  sConfig.IC1Prescaler = TIM_ICPSC_DIV1;
  sConfig.IC1Filter = 0;
  sConfig.IC2Polarity = TIM_ICPOLARITY_RISING;
  sConfig.IC2Selection = TIM_ICSELECTION_DIRECTTI;
  sConfig.IC2Prescaler = TIM_ICPSC_DIV1;
  sConfig.IC2Filter = 0;
  if (HAL_TIM_Encoder_Init(&htim5, &sConfig) != HAL_OK)
  {
    Error_Handler();
  }
  sMasterConfig.MasterOutputTrigger = TIM_TRGO_RESET;
  sMasterConfig.MasterSlaveMode = TIM_MASTERSLAVEMODE_DISABLE;
  if (HAL_TIMEx_MasterConfigSynchronization(&htim5, &sMasterConfig) != HAL_OK)
  {
    Error_Handler();
  }

}

static void MX_TIM6_Init(void)
{

  TIM_MasterConfigTypeDef sMasterConfig = {0};

  htim6.Instance = TIM6;
  htim6.Init.Prescaler = 239;
  htim6.Init.CounterMode = TIM_COUNTERMODE_UP;
  htim6.Init.Period = 999;
  htim6.Init.AutoReloadPreload = TIM_AUTORELOAD_PRELOAD_ENABLE;
  if (HAL_TIM_Base_Init(&htim6) != HAL_OK)
  {
    Error_Handler();
  }
  sMasterConfig.MasterOutputTrigger = TIM_TRGO_UPDATE;
  sMasterConfig.MasterSlaveMode = TIM_MASTERSLAVEMODE_DISABLE;
  if (HAL_TIMEx_MasterConfigSynchronization(&htim6, &sMasterConfig) != HAL_OK)
  {
    Error_Handler();
  }

}

static void MX_TIM8_Init(void)
{

  TIM_MasterConfigTypeDef sMasterConfig = {0};
  TIM_OC_InitTypeDef sConfigOC = {0};
  TIM_BreakDeadTimeConfigTypeDef sBreakDeadTimeConfig = {0};

  htim8.Instance = TIM8;
  htim8.Init.Prescaler = 1;
  htim8.Init.CounterMode = TIM_COUNTERMODE_UP;
  htim8.Init.Period = 9999;
  htim8.Init.ClockDivision = TIM_CLOCKDIVISION_DIV1;
  htim8.Init.RepetitionCounter = 0;
  htim8.Init.AutoReloadPreload = TIM_AUTORELOAD_PRELOAD_ENABLE;
  if (HAL_TIM_PWM_Init(&htim8) != HAL_OK)
  {
    Error_Handler();
  }
  sMasterConfig.MasterOutputTrigger = TIM_TRGO_RESET;
  sMasterConfig.MasterOutputTrigger2 = TIM_TRGO2_RESET;
  sMasterConfig.MasterSlaveMode = TIM_MASTERSLAVEMODE_DISABLE;
  if (HAL_TIMEx_MasterConfigSynchronization(&htim8, &sMasterConfig) != HAL_OK)
  {
    Error_Handler();
  }
  sConfigOC.OCMode = TIM_OCMODE_PWM1;
  sConfigOC.Pulse = 0;
  sConfigOC.OCPolarity = TIM_OCPOLARITY_HIGH;
  sConfigOC.OCNPolarity = TIM_OCNPOLARITY_HIGH;
  sConfigOC.OCFastMode = TIM_OCFAST_DISABLE;
  sConfigOC.OCIdleState = TIM_OCIDLESTATE_RESET;
  sConfigOC.OCNIdleState = TIM_OCNIDLESTATE_RESET;
  if (HAL_TIM_PWM_ConfigChannel(&htim8, &sConfigOC, TIM_CHANNEL_1) != HAL_OK)
  {
    Error_Handler();
  }
  if (HAL_TIM_PWM_ConfigChannel(&htim8, &sConfigOC, TIM_CHANNEL_2) != HAL_OK)
  {
    Error_Handler();
  }
  if (HAL_TIM_PWM_ConfigChannel(&htim8, &sConfigOC, TIM_CHANNEL_3) != HAL_OK)
  {
    Error_Handler();
  }
  if (HAL_TIM_PWM_ConfigChannel(&htim8, &sConfigOC, TIM_CHANNEL_4) != HAL_OK)
  {
    Error_Handler();
  }
  sBreakDeadTimeConfig.OffStateRunMode = TIM_OSSR_DISABLE;
  sBreakDeadTimeConfig.OffStateIDLEMode = TIM_OSSI_DISABLE;
  sBreakDeadTimeConfig.LockLevel = TIM_LOCKLEVEL_OFF;
  sBreakDeadTimeConfig.DeadTime = 0;
  sBreakDeadTimeConfig.BreakState = TIM_BREAK_DISABLE;
  sBreakDeadTimeConfig.BreakPolarity = TIM_BREAKPOLARITY_HIGH;
  sBreakDeadTimeConfig.BreakFilter = 0;
  sBreakDeadTimeConfig.Break2State = TIM_BREAK2_DISABLE;
  sBreakDeadTimeConfig.Break2Polarity = TIM_BREAK2POLARITY_HIGH;
  sBreakDeadTimeConfig.Break2Filter = 0;
  sBreakDeadTimeConfig.AutomaticOutput = TIM_AUTOMATICOUTPUT_DISABLE;
  if (HAL_TIMEx_ConfigBreakDeadTime(&htim8, &sBreakDeadTimeConfig) != HAL_OK)
  {
    Error_Handler();
  }
  HAL_TIM_MspPostInit(&htim8);

}

static void MX_TIM12_Init(void)
{

  TIM_ClockConfigTypeDef sClockSourceConfig = {0};
  TIM_MasterConfigTypeDef sMasterConfig = {0};

  htim12.Instance = TIM12;
  htim12.Init.Prescaler = 239;
  htim12.Init.CounterMode = TIM_COUNTERMODE_UP;
  htim12.Init.Period = 65535;
  htim12.Init.ClockDivision = TIM_CLOCKDIVISION_DIV1;
  htim12.Init.AutoReloadPreload = TIM_AUTORELOAD_PRELOAD_ENABLE;
  if (HAL_TIM_Base_Init(&htim12) != HAL_OK)
  {
    Error_Handler();
  }
  sClockSourceConfig.ClockSource = TIM_CLOCKSOURCE_INTERNAL;
  if (HAL_TIM_ConfigClockSource(&htim12, &sClockSourceConfig) != HAL_OK)
  {
    Error_Handler();
  }
  sMasterConfig.MasterOutputTrigger = TIM_TRGO_UPDATE;
  sMasterConfig.MasterSlaveMode = TIM_MASTERSLAVEMODE_ENABLE;
  if (HAL_TIMEx_MasterConfigSynchronization(&htim12, &sMasterConfig) != HAL_OK)
  {
    Error_Handler();
  }

}

static void MX_TIM15_Init(void)
{

  TIM_ClockConfigTypeDef sClockSourceConfig = {0};
  TIM_MasterConfigTypeDef sMasterConfig = {0};
  TIM_OC_InitTypeDef sConfigOC = {0};
  TIM_BreakDeadTimeConfigTypeDef sBreakDeadTimeConfig = {0};

  htim15.Instance = TIM15;
  htim15.Init.Prescaler = 119;
  htim15.Init.CounterMode = TIM_COUNTERMODE_UP;
  htim15.Init.Period = 49;
  htim15.Init.ClockDivision = TIM_CLOCKDIVISION_DIV1;
  htim15.Init.RepetitionCounter = 0;
  htim15.Init.AutoReloadPreload = TIM_AUTORELOAD_PRELOAD_DISABLE;
  if (HAL_TIM_Base_Init(&htim15) != HAL_OK)
  {
    Error_Handler();
  }
  sClockSourceConfig.ClockSource = TIM_CLOCKSOURCE_INTERNAL;
  if (HAL_TIM_ConfigClockSource(&htim15, &sClockSourceConfig) != HAL_OK)
  {
    Error_Handler();
  }
  if (HAL_TIM_PWM_Init(&htim15) != HAL_OK)
  {
    Error_Handler();
  }
  sMasterConfig.MasterOutputTrigger = TIM_TRGO_RESET;
  sMasterConfig.MasterSlaveMode = TIM_MASTERSLAVEMODE_DISABLE;
  if (HAL_TIMEx_MasterConfigSynchronization(&htim15, &sMasterConfig) != HAL_OK)
  {
    Error_Handler();
  }
  sConfigOC.OCMode = TIM_OCMODE_PWM1;
  sConfigOC.Pulse = 0;
  sConfigOC.OCPolarity = TIM_OCPOLARITY_HIGH;
  sConfigOC.OCNPolarity = TIM_OCNPOLARITY_HIGH;
  sConfigOC.OCFastMode = TIM_OCFAST_DISABLE;
  sConfigOC.OCIdleState = TIM_OCIDLESTATE_RESET;
  sConfigOC.OCNIdleState = TIM_OCNIDLESTATE_RESET;
  if (HAL_TIM_PWM_ConfigChannel(&htim15, &sConfigOC, TIM_CHANNEL_1) != HAL_OK)
  {
    Error_Handler();
  }
  sBreakDeadTimeConfig.OffStateRunMode = TIM_OSSR_DISABLE;
  sBreakDeadTimeConfig.OffStateIDLEMode = TIM_OSSI_DISABLE;
  sBreakDeadTimeConfig.LockLevel = TIM_LOCKLEVEL_OFF;
  sBreakDeadTimeConfig.DeadTime = 0;
  sBreakDeadTimeConfig.BreakState = TIM_BREAK_DISABLE;
  sBreakDeadTimeConfig.BreakPolarity = TIM_BREAKPOLARITY_HIGH;
  sBreakDeadTimeConfig.BreakFilter = 0;
  sBreakDeadTimeConfig.AutomaticOutput = TIM_AUTOMATICOUTPUT_DISABLE;
  if (HAL_TIMEx_ConfigBreakDeadTime(&htim15, &sBreakDeadTimeConfig) != HAL_OK)
  {
    Error_Handler();
  }
  HAL_TIM_MspPostInit(&htim15);

}

static void MX_TIM16_Init(void)
{

  TIM_OC_InitTypeDef sConfigOC = {0};
  TIM_BreakDeadTimeConfigTypeDef sBreakDeadTimeConfig = {0};

  htim16.Instance = TIM16;
  htim16.Init.Prescaler = 239;
  htim16.Init.CounterMode = TIM_COUNTERMODE_UP;
  htim16.Init.Period = 65535;
  htim16.Init.ClockDivision = TIM_CLOCKDIVISION_DIV1;
  htim16.Init.RepetitionCounter = 0;
  htim16.Init.AutoReloadPreload = TIM_AUTORELOAD_PRELOAD_DISABLE;
  if (HAL_TIM_Base_Init(&htim16) != HAL_OK)
  {
    Error_Handler();
  }
  if (HAL_TIM_PWM_Init(&htim16) != HAL_OK)
  {
    Error_Handler();
  }
  sConfigOC.OCMode = TIM_OCMODE_PWM1;
  sConfigOC.Pulse = 0;
  sConfigOC.OCPolarity = TIM_OCPOLARITY_HIGH;
  sConfigOC.OCNPolarity = TIM_OCNPOLARITY_HIGH;
  sConfigOC.OCFastMode = TIM_OCFAST_DISABLE;
  sConfigOC.OCIdleState = TIM_OCIDLESTATE_RESET;
  sConfigOC.OCNIdleState = TIM_OCNIDLESTATE_RESET;
  if (HAL_TIM_PWM_ConfigChannel(&htim16, &sConfigOC, TIM_CHANNEL_1) != HAL_OK)
  {
    Error_Handler();
  }
  sBreakDeadTimeConfig.OffStateRunMode = TIM_OSSR_DISABLE;
  sBreakDeadTimeConfig.OffStateIDLEMode = TIM_OSSI_DISABLE;
  sBreakDeadTimeConfig.LockLevel = TIM_LOCKLEVEL_OFF;
  sBreakDeadTimeConfig.DeadTime = 0;
  sBreakDeadTimeConfig.BreakState = TIM_BREAK_DISABLE;
  sBreakDeadTimeConfig.BreakPolarity = TIM_BREAKPOLARITY_HIGH;
  sBreakDeadTimeConfig.BreakFilter = 0;
  sBreakDeadTimeConfig.AutomaticOutput = TIM_AUTOMATICOUTPUT_DISABLE;
  if (HAL_TIMEx_ConfigBreakDeadTime(&htim16, &sBreakDeadTimeConfig) != HAL_OK)
  {
    Error_Handler();
  }
  HAL_TIM_MspPostInit(&htim16);

}

static void MX_TIM17_Init(void)
{

  TIM_OC_InitTypeDef sConfigOC = {0};
  TIM_BreakDeadTimeConfigTypeDef sBreakDeadTimeConfig = {0};

  htim17.Instance = TIM17;
  htim17.Init.Prescaler = 0;
  htim17.Init.CounterMode = TIM_COUNTERMODE_UP;
  htim17.Init.Period = 299;
  htim17.Init.ClockDivision = TIM_CLOCKDIVISION_DIV1;
  htim17.Init.RepetitionCounter = 0;
  htim17.Init.AutoReloadPreload = TIM_AUTORELOAD_PRELOAD_DISABLE;
  if (HAL_TIM_Base_Init(&htim17) != HAL_OK)
  {
    Error_Handler();
  }
  if (HAL_TIM_PWM_Init(&htim17) != HAL_OK)
  {
    Error_Handler();
  }
  sConfigOC.OCMode = TIM_OCMODE_PWM1;
  sConfigOC.Pulse = 0;
  sConfigOC.OCPolarity = TIM_OCPOLARITY_HIGH;
  sConfigOC.OCNPolarity = TIM_OCNPOLARITY_HIGH;
  sConfigOC.OCFastMode = TIM_OCFAST_DISABLE;
  sConfigOC.OCIdleState = TIM_OCIDLESTATE_RESET;
  sConfigOC.OCNIdleState = TIM_OCNIDLESTATE_RESET;
  if (HAL_TIM_PWM_ConfigChannel(&htim17, &sConfigOC, TIM_CHANNEL_1) != HAL_OK)
  {
    Error_Handler();
  }
  sBreakDeadTimeConfig.OffStateRunMode = TIM_OSSR_DISABLE;
  sBreakDeadTimeConfig.OffStateIDLEMode = TIM_OSSI_DISABLE;
  sBreakDeadTimeConfig.LockLevel = TIM_LOCKLEVEL_OFF;
  sBreakDeadTimeConfig.DeadTime = 0;
  sBreakDeadTimeConfig.BreakState = TIM_BREAK_DISABLE;
  sBreakDeadTimeConfig.BreakPolarity = TIM_BREAKPOLARITY_HIGH;
  sBreakDeadTimeConfig.BreakFilter = 0;
  sBreakDeadTimeConfig.AutomaticOutput = TIM_AUTOMATICOUTPUT_DISABLE;
  if (HAL_TIMEx_ConfigBreakDeadTime(&htim17, &sBreakDeadTimeConfig) != HAL_OK)
  {
    Error_Handler();
  }
  HAL_TIM_MspPostInit(&htim17);

}

static void MX_USART1_UART_Init(void)
{

  huart1.Instance = USART1;
  huart1.Init.BaudRate = 921600;
  huart1.Init.WordLength = UART_WORDLENGTH_8B;
  huart1.Init.StopBits = UART_STOPBITS_1;
  huart1.Init.Parity = UART_PARITY_NONE;
  huart1.Init.Mode = UART_MODE_TX_RX;
  huart1.Init.HwFlowCtl = UART_HWCONTROL_NONE;
  huart1.Init.OverSampling = UART_OVERSAMPLING_16;
  huart1.Init.OneBitSampling = UART_ONE_BIT_SAMPLE_DISABLE;
  huart1.Init.ClockPrescaler = UART_PRESCALER_DIV1;
  huart1.AdvancedInit.AdvFeatureInit = UART_ADVFEATURE_NO_INIT;
  if (HAL_UART_Init(&huart1) != HAL_OK)
  {
    Error_Handler();
  }
  if (HAL_UARTEx_SetTxFifoThreshold(&huart1, UART_TXFIFO_THRESHOLD_1_8) != HAL_OK)
  {
    Error_Handler();
  }
  if (HAL_UARTEx_SetRxFifoThreshold(&huart1, UART_RXFIFO_THRESHOLD_1_8) != HAL_OK)
  {
    Error_Handler();
  }
  if (HAL_UARTEx_DisableFifoMode(&huart1) != HAL_OK)
  {
    Error_Handler();
  }

}

static void MX_USART2_UART_Init(void)
{

  huart2.Instance = USART2;
  huart2.Init.BaudRate = 921600;
  huart2.Init.WordLength = UART_WORDLENGTH_8B;
  huart2.Init.StopBits = UART_STOPBITS_1;
  huart2.Init.Parity = UART_PARITY_NONE;
  huart2.Init.Mode = UART_MODE_TX_RX;
  huart2.Init.HwFlowCtl = UART_HWCONTROL_NONE;
  huart2.Init.OverSampling = UART_OVERSAMPLING_16;
  huart2.Init.OneBitSampling = UART_ONE_BIT_SAMPLE_DISABLE;
  huart2.Init.ClockPrescaler = UART_PRESCALER_DIV1;
  huart2.AdvancedInit.AdvFeatureInit = UART_ADVFEATURE_NO_INIT;
  if (HAL_UART_Init(&huart2) != HAL_OK)
  {
    Error_Handler();
  }
  if (HAL_UARTEx_SetTxFifoThreshold(&huart2, UART_TXFIFO_THRESHOLD_1_8) != HAL_OK)
  {
    Error_Handler();
  }
  if (HAL_UARTEx_SetRxFifoThreshold(&huart2, UART_RXFIFO_THRESHOLD_1_8) != HAL_OK)
  {
    Error_Handler();
  }
  if (HAL_UARTEx_DisableFifoMode(&huart2) != HAL_OK)
  {
    Error_Handler();
  }

}

static void MX_USART3_UART_Init(void)
{

  huart3.Instance = USART3;
  huart3.Init.BaudRate = 921600;
  huart3.Init.WordLength = UART_WORDLENGTH_8B;
  huart3.Init.StopBits = UART_STOPBITS_1;
  huart3.Init.Parity = UART_PARITY_NONE;
  huart3.Init.Mode = UART_MODE_TX_RX;
  huart3.Init.HwFlowCtl = UART_HWCONTROL_NONE;
  huart3.Init.OverSampling = UART_OVERSAMPLING_16;
  huart3.Init.OneBitSampling = UART_ONE_BIT_SAMPLE_DISABLE;
  huart3.Init.ClockPrescaler = UART_PRESCALER_DIV1;
  huart3.AdvancedInit.AdvFeatureInit = UART_ADVFEATURE_NO_INIT;
  if (HAL_UART_Init(&huart3) != HAL_OK)
  {
    Error_Handler();
  }
  if (HAL_UARTEx_SetTxFifoThreshold(&huart3, UART_TXFIFO_THRESHOLD_1_8) != HAL_OK)
  {
    Error_Handler();
  }
  if (HAL_UARTEx_SetRxFifoThreshold(&huart3, UART_RXFIFO_THRESHOLD_1_8) != HAL_OK)
  {
    Error_Handler();
  }
  if (HAL_UARTEx_DisableFifoMode(&huart3) != HAL_OK)
  {
    Error_Handler();
  }

}

static void MX_DMA_Init(void)
{

  /* DMA controller clock enable */
  __HAL_RCC_DMA2_CLK_ENABLE();
  __HAL_RCC_DMA1_CLK_ENABLE();

  /* DMA interrupt init */
  /* DMA2_Stream0_IRQn interrupt configuration */
  HAL_NVIC_SetPriority(DMA2_Stream0_IRQn, 5, 0);
  HAL_NVIC_EnableIRQ(DMA2_Stream0_IRQn);

}

static void MX_GPIO_Init(void)
{
  GPIO_InitTypeDef GPIO_InitStruct = {0};

  /* GPIO Ports Clock Enable */
  __HAL_RCC_GPIOE_CLK_ENABLE();
  __HAL_RCC_GPIOH_CLK_ENABLE();
  __HAL_RCC_GPIOA_CLK_ENABLE();
  __HAL_RCC_GPIOC_CLK_ENABLE();
  __HAL_RCC_GPIOB_CLK_ENABLE();
  __HAL_RCC_GPIOD_CLK_ENABLE();

  /*Configure GPIO pin Output Level */
  HAL_GPIO_WritePin(tft_nss_GPIO_Port, tft_nss_Pin, GPIO_PIN_SET);

  /*Configure GPIO pin Output Level */
  HAL_GPIO_WritePin(GPIOD, tft_rs_Pin|tft_rst_Pin, GPIO_PIN_SET);

  /*Configure GPIO pin : tft_nss_Pin */
  GPIO_InitStruct.Pin = tft_nss_Pin;
  GPIO_InitStruct.Mode = GPIO_MODE_OUTPUT_PP;
  GPIO_InitStruct.Pull = GPIO_NOPULL;
  GPIO_InitStruct.Speed = GPIO_SPEED_FREQ_VERY_HIGH;
  HAL_GPIO_Init(tft_nss_GPIO_Port, &GPIO_InitStruct);

  /*Configure GPIO pins : key0_Pin key1_Pin */
  GPIO_InitStruct.Pin = key0_Pin|key1_Pin;
  GPIO_InitStruct.Mode = GPIO_MODE_INPUT;
  GPIO_InitStruct.Pull = GPIO_NOPULL;
  HAL_GPIO_Init(GPIOB, &GPIO_InitStruct);

  /*Configure GPIO pins : tft_rs_Pin tft_rst_Pin */
  GPIO_InitStruct.Pin = tft_rs_Pin|tft_rst_Pin;
  GPIO_InitStruct.Mode = GPIO_MODE_OUTPUT_PP;
  GPIO_InitStruct.Pull = GPIO_NOPULL;
  GPIO_InitStruct.Speed = GPIO_SPEED_FREQ_VERY_HIGH;
  HAL_GPIO_Init(GPIOD, &GPIO_InitStruct);

}

__weak void lcdTask(void *argument)
{
  for(;;)
  {
    osDelay(1);
  }
}

__weak void motorControlTask(void *argument)
{
  for(;;)
  {
    osDelay(1);
  }
}

 /* MPU Configuration */

void MPU_Config(void)
{
  MPU_Region_InitTypeDef MPU_InitStruct = {0};

  /* Disables the MPU */
  HAL_MPU_Disable();

  /** Initializes and configures the Region and the memory to be protected
  */
  MPU_InitStruct.Enable = MPU_REGION_ENABLE;
  MPU_InitStruct.Number = MPU_REGION_NUMBER0;
  MPU_InitStruct.BaseAddress = 0x30000000;
  MPU_InitStruct.Size = MPU_REGION_SIZE_128KB;
  MPU_InitStruct.SubRegionDisable = 0x00;
  MPU_InitStruct.TypeExtField = MPU_TEX_LEVEL0;
  MPU_InitStruct.AccessPermission = MPU_REGION_FULL_ACCESS;
  MPU_InitStruct.DisableExec = MPU_INSTRUCTION_ACCESS_DISABLE;
  MPU_InitStruct.IsShareable = MPU_ACCESS_SHAREABLE;
  MPU_InitStruct.IsCacheable = MPU_ACCESS_NOT_CACHEABLE;
  MPU_InitStruct.IsBufferable = MPU_ACCESS_NOT_BUFFERABLE;

  HAL_MPU_ConfigRegion(&MPU_InitStruct);
  /* Enables the MPU */
  HAL_MPU_Enable(MPU_PRIVILEGED_DEFAULT);

}

void HAL_TIM_PeriodElapsedCallback(TIM_HandleTypeDef *htim)
{
  if (htim->Instance == TIM7)
  {
    HAL_IncTick();
  }
  /* USER CODE BEGIN Callback 1 */
    if (htim->Instance == TIM12) {
        timestamp_us += 65536ULL;
        runtime_base32 += 65536ULL;
    }
  /* USER CODE END Callback 1 */
}

void Error_Handler(void)
{
  __disable_irq();
  while (1)
  {
  }
}
